# ATSAMRH707F18A register map
Vendor: Microchip Technology; Series: SAMRH707; File version: 0
CPU: CM7 r1p1, little endian, MPU, FPU, double-precision FPU, I-cache, D-cache, ITCM, DTCM, 3 interrupt priority bits, 69 interrupts
Registers are 32-bit, read-write, reset 0x0 unless marked. A register's access mark holds for its fields unless they carry their own. Offsets are from the block's base; [hi:lo] are bit positions; {n}, {i} and the like mark numbered series.

## ADC — Analog-to-Digital Converter
Base 0x40200000
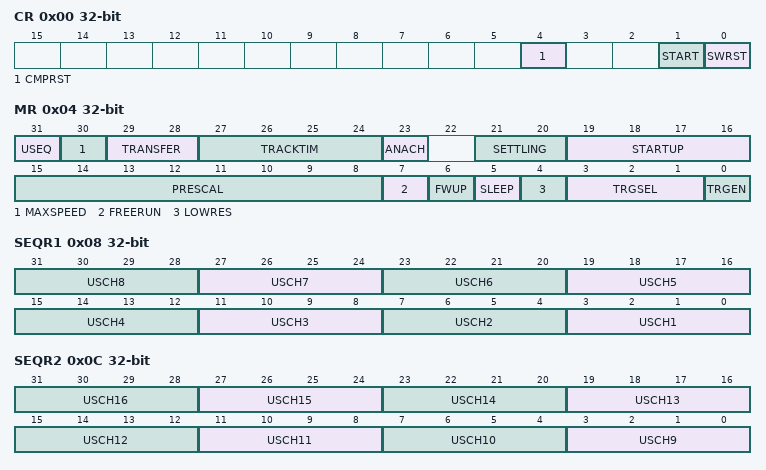
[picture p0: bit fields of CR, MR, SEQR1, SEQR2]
0x00 CR wo — Control Register
  [4] CMPRST — Comparison Restart
  [1] START — Start Conversion
  [0] SWRST — Software Reset
0x04 MR — Mode Register
  [31] USEQ — User Sequence Enable
    0=NUM_ORDER (Normal mode: The controller converts channels in a simple numeric order depending only on the channel index.); 1=REG_ORDER (User Sequence mode: The sequence respects what is defined in ADC_SEQR1 and ADC_SEQR2 registers and can be used to convert the same channel several times.)
  [30] MAXSPEED — Maximum Sampling Rate Enable in Freerun Mode
  [29:28] TRANSFER — Transfer Time
  [27:24] TRACKTIM — Tracking Time
  [23] ANACH — Analog Change
    0=NONE (No analog change on channel switching: DIFF0, OFF0 and GAIN0 are used for all channels.); 1=ALLOWED (Allows different analog settings for each channel. See ADC_CGR and ADC_COR)
  [21:20] SETTLING — Analog Settlings Time
    0=AST3 (3 periods of ADCCLK); 1=AST5 (5 periods of ADCCLK); 2=AST9 (9 periods of ADCCLK); 3=AST17 (17 periods of ADCCLK)
  [19:16] STARTUP — Startup Time
    0=SUT0 (0 periods of ADCCLK); 1=SUT8 (8 periods of ADCCLK); 2=SUT16 (16 periods of ADCCLK); 3=SUT24 (24 periods of ADCCLK); 4=SUT64 (64 periods of ADCCLK); 5=SUT80 (80 periods of ADCCLK); 6=SUT96 (96 periods of ADCCLK); 7=SUT112 (112 periods of ADCCLK); 8=SUT512 (512 periods of ADCCLK); 9=SUT576 (576 periods of ADCCLK); 10=SUT640 (640 periods of ADCCLK); 11=SUT704 (704 periods of ADCCLK); 12=SUT768 (768 periods of ADCCLK); 13=SUT832 (832 periods of ADCCLK); 14=SUT896 (896 periods of ADCCLK); 15=SUT960 (960 periods of ADCCLK)
  [15:8] PRESCAL — Prescaler Rate Selection
  [7] FREERUN — Free running
    0=OFF (Normal Mode); 1=ON (Free Run Mode: Never wait for any trigger.)
  [6] FWUP — Fast Wakeup
    0=OFF (If SLEEP is 1, then both ADC core and reference voltage circuitry are OFF between conversions); 1=ON (If SLEEP is 1, then Fast Wakeup Sleep mode: The voltage reference is ON between conversions and ADC core is OFF)
  [5] SLEEP — Sleep Mode
    0=NORMAL (Normal Mode: The ADC core and reference voltage circuitry are kept ON between conversions.); 1=SLEEP (Sleep Mode: The wakeup time can be modified by programming the FWUP bit.)
  [4] LOWRES — Low resolution
    0=BITS_RESOLUTION (RESOLUTION-bit resolution.); 1=BITS_RESOLUTION_2 (RESOLUTION_2-bit resolution)
  [3:1] TRGSEL — Trigger Selection
    0=ADC_TRIG0 (ADTRG); 1=ADC_TRIG1 (TIOA0); 2=ADC_TRIG2 (TIOA1); 3=ADC_TRIG3 (TIOA2); 4=ADC_TRIG4 (PWM0 Event 0); 5=ADC_TRIG5 (PWM0 Event 1); 6=ADC_TRIG6 (PWM1 Event 0); 7=ADC_TRIG7 (PWM1 Event 1)
  [0] TRGEN — Trigger Enable
    0=DIS (Hardware triggers are disabled. Starting a conversion is only possible by software.); 1=EN (Hardware trigger selected by TRGSEL is enabled. (rising mode selected))
0x08 SEQR1 — Channel Sequence Register 1
  [4n-1:4n-4] USCH{n} (n=1..8) — User Sequence Number {n}
0x0C SEQR2 — Channel Sequence Register 2
  [4n-33:4n-36] USCH{n} (n=9..16) — User Sequence Number {n}
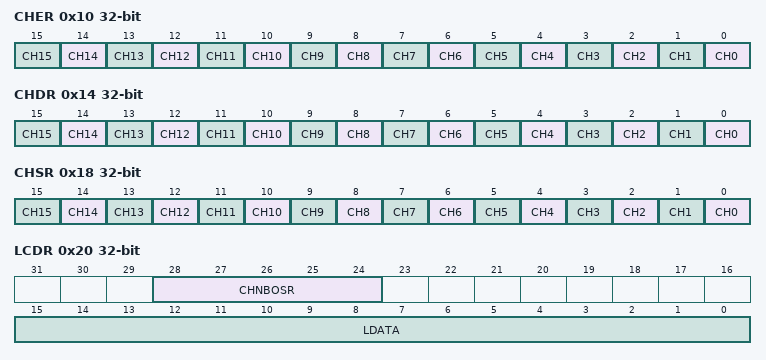
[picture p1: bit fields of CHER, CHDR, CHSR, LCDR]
0x10 CHER wo — Channel Enable Register
  [n] CH{n} (n=0..15) — Channel {n} Enable
0x14 CHDR wo — Channel Disable Register
  [n] CH{n} (n=0..15) — Channel {n} Disable
0x18 CHSR ro — Channel Status Register
  [n] CH{n} (n=0..15) — Channel {n} Status
0x20 LCDR ro — Last Converted Data Register
  [28:24] CHNBOSR — Channel Number in Oversampling Mode
  [15:0] LDATA — Last Data Converted
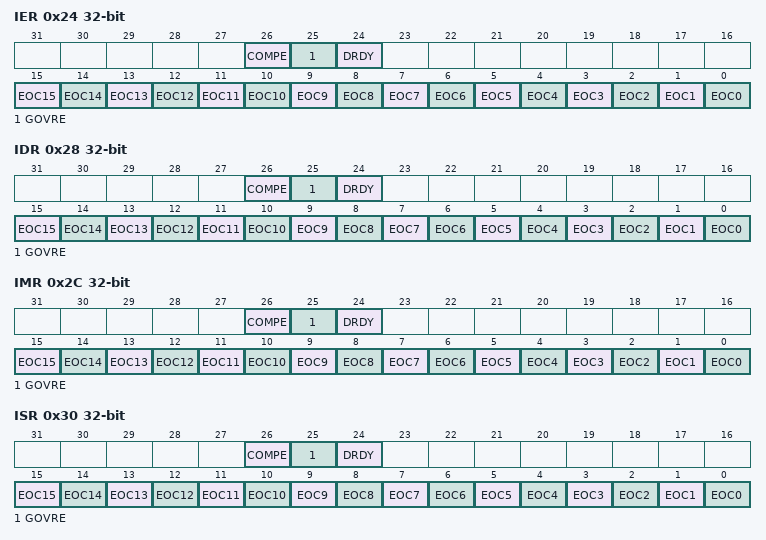
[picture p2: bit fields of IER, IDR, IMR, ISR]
0x24 IER wo — Interrupt Enable Register
  [26] COMPE — Comparison Event Interrupt Enable
  [25] GOVRE — General Overrun Error Interrupt Enable
  [24] DRDY — Data Ready Interrupt Enable
  [n] EOC{n} (n=0..15) — End of Conversion Interrupt Enable {n}
0x28 IDR wo — Interrupt Disable Register
  [26] COMPE — Comparison Event Interrupt Disable
  [25] GOVRE — General Overrun Error Interrupt Disable
  [24] DRDY — Data Ready Interrupt Disable
  [n] EOC{n} (n=0..15) — End of Conversion Interrupt Disable {n}
0x2C IMR ro — Interrupt Mask Register
  [26] COMPE — Comparison Event Interrupt Mask
  [25] GOVRE — General Overrun Error Interrupt Mask
  [24] DRDY — Data Ready Interrupt Mask
  [n] EOC{n} (n=0..15) — End of Conversion Interrupt Mask {n}
0x30 ISR ro — Interrupt Status Register
  [26] COMPE — Comparison Event (cleared on read)
  [25] GOVRE — General Overrun Error (cleared on read)
  [24] DRDY — Data Ready (automatically set / cleared)
  [n] EOC{n} (n=0..15) — End of Conversion {n} (automatically set / cleared)
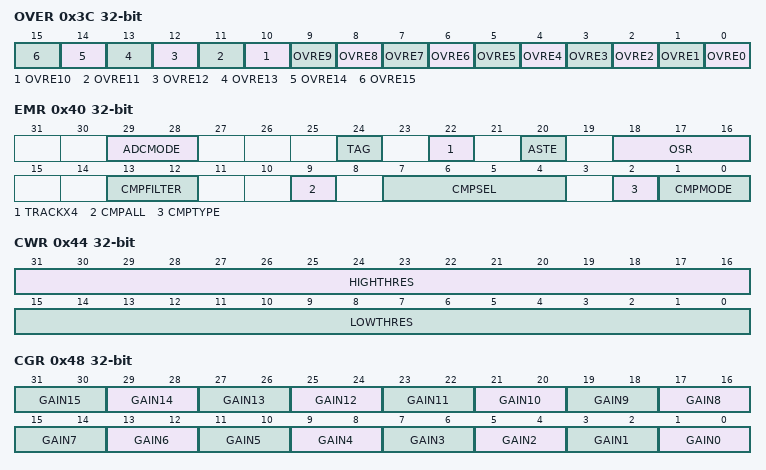
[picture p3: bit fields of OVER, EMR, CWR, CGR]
0x3C OVER ro — Overrun Status Register
  [n] OVRE{n} (n=0..15) — Overrun Error {n}
0x40 EMR — Extended Mode Register
  [29:28] ADCMODE — ADC Running Mode
    0=NORMAL (Normal mode of operation.); 1=OFFSET_ERROR (Offset Error mode to measure the offset error. See Table 7-6.); 2=GAIN_ERROR_HIGH (Gain Error mode to measure the gain error. See Table 7-6.); 3=GAIN_ERROR_LOW (Gain Error mode to measure the gain error. See Table 7-6.)
  [24] TAG — Tag of ADC_LCDR
  [22] TRACKX4 — Tracking time x4
    0=TRACK1 (The ADC_MR.TRACKTIM field effect is multiplied by 1.); 1=TRACK4 (The ADC_MR.TRACKTIM field effect is multiplied by 4.)
  [20] ASTE — Averaging on Single Trigger Event
    0=MULTI_TRIG_AVERAGE (The average requests several trigger events.); 1=SINGLE_TRIG_AVERAGE (The average requests only one trigger event.)
  [18:16] OSR — Over Sampling Rate
    0=NO_AVERAGE (No averaging. ADC sample rate is maximum.); 1=1-bit enhanced resolution by averaging. ADC sample rate divided by 4.; 2=2-bit enhanced resolution by averaging. ADC sample rate divided by 16.; 3=3-bit enhanced resolution by averaging. ADC sample rate divided by 64.; 4=4-bit enhanced resolution by averaging. ADC sample rate divided by 256.
  [13:12] CMPFILTER — Compare Event Filtering
  [9] CMPALL — Compare All Channels
  [7:4] CMPSEL — Comparison Selected Channel
  [2] CMPTYPE — Comparison Type
    0=FLAG_ONLY (Any conversion is performed and comparison function drives the ADC_ISR.COMPE flag.); 1=START_CONDITION (Comparison conditions must be met to start the storage of all conversions until the ADC_CR.CMPRST bit is set.)
  [1:0] CMPMODE — Comparison Mode
    0=LOW (When the converted data is lower than the low threshold of the window, generates the ADC_ISR.COMPE flag or, in Partial Wakeup mode, defines the conditions to exit system from Wait mode.); 1=HIGH (When the converted data is higher than the high threshold of the window, generates the ADC_ISR.COMPE flag or, in Partial Wakeup mode, defines the conditions to exit system from Wait mode.); 2=IN (When the converted data is in the comparison window, generates the ADC_ISR.COMPE flag or, in Partial Wakeup mode, defines the conditions to exit system from Wait mode.); 3=OUT (When the converted data is out of the comparison window, generates the ADC_ISR.COMPE flag or, in Partial Wakeup mode, defines the conditions to exit system from Wait mode.)
0x44 CWR — Compare Window Register
  [31:16] HIGHTHRES — High Threshold
  [15:0] LOWTHRES — Low Threshold
0x48 CGR — Channel Gain Register
  [all] fields
    0=SE1_DIFF0_5 (Single-ended gain = 1 (ADC_COR.DIFFx = 0), differential gain = 0.5 (ADC_COR.DIFFx = 1)); 1=SE1_DIFF1 (Single-ended gain = 1 (ADC_COR.DIFFx = 0), differential gain = 1 (ADC_COR.DIFFx = 1)); 2=SE2_DIFF2 (Single-ended gain = 2 (ADC_COR.DIFFx = 0), differential gain = 2 (ADC_COR.DIFFx = 1)); 3=SE4_DIFF2 (Single-ended gain = 4 (ADC_COR.DIFFx = 0), differential gain = 2 (ADC_COR.DIFFx = 1))
  [2n+1:2n] GAIN{n} (n=0..15) — Gain for Channel {n}
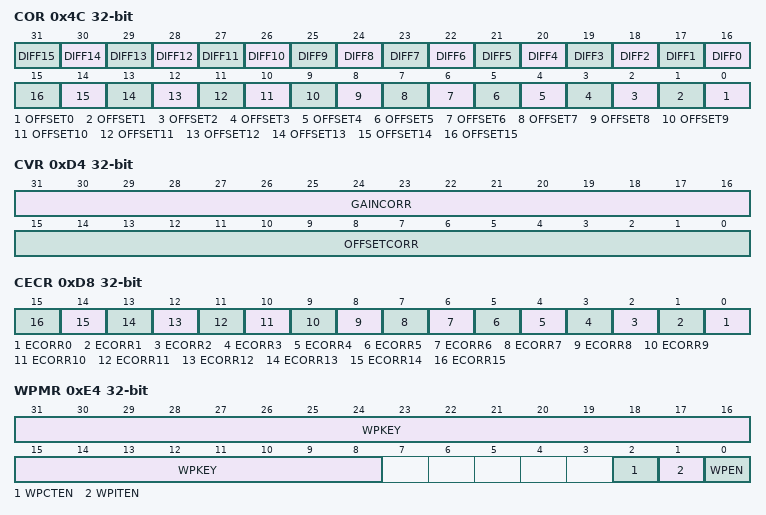
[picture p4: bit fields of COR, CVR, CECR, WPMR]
0x4C COR — Channel Offset Register
  [n+16] DIFF{n} (n=0..15) — Differential Inputs for Channel {n}
  [n] OFFSET{n} (n=0..15)
{0x50+4i} CDR[{i}] (i=0..15) ro — Channel Data Register
  [15:0] DATA — Converted Data
0x94 ACR — Analog Control Register
  [9:8] IBCTL — ADC Bias Current Control
0xD4 CVR — Correction Values Register
  [31:16] GAINCORR — Gain Correction
  [15:0] OFFSETCORR — Offset Correction
0xD8 CECR — Channel Error Correction Register
  [n] ECORR{n} (n=0..15) — Error Correction Enable for channel {n}
0xE4 WPMR — Write Protection Mode Register
  [31:8] WPKEY — Write Protection Key
    0x414443=PASSWD (Writing any other value in this field aborts the write operation of the WPEN bit. Always reads as 0)
  [2] WPCTEN — Write Protection Control Enable
  [1] WPITEN — Write Protection Interrupt Enable
  [0] WPEN — Write Protection Enable
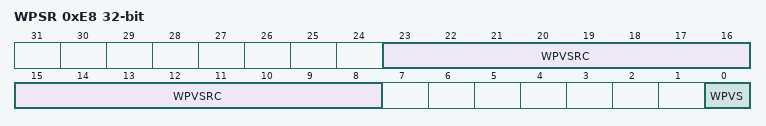
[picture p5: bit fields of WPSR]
0xE8 WPSR ro — Write Protection Status Register
  [23:8] WPVSRC — Write Protection Violation Source
  [0] WPVS — Write Protection Violation Status
